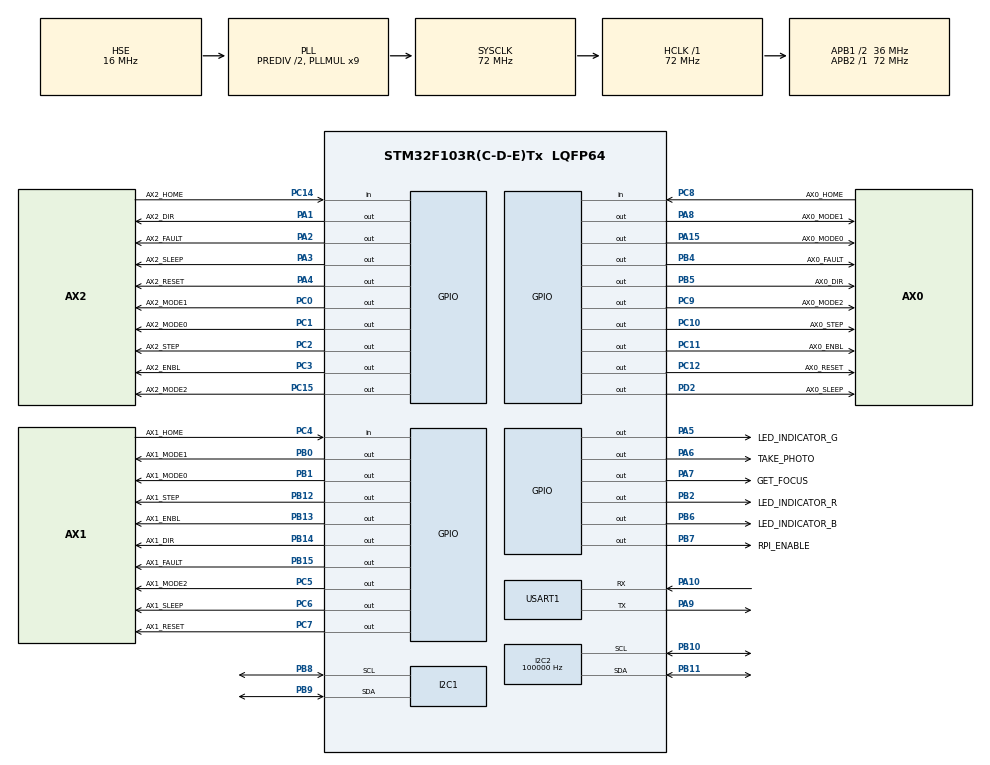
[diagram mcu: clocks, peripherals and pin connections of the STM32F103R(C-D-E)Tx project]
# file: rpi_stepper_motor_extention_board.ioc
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Dma.Request0=USART1_TX
Dma.Request1=USART1_RX
Dma.USART1_RX.1.Direction=DMA_PERIPH_TO_MEMORY
Dma.USART1_RX.1.Instance=DMA1_Channel5
Dma.USART1_RX.1.MemDataAlignment=DMA_MDATAALIGN_BYTE
Dma.USART1_RX.1.MemInc=DMA_MINC_ENABLE
Dma.USART1_RX.1.Mode=DMA_NORMAL
Dma.USART1_RX.1.PeriphDataAlignment=DMA_PDATAALIGN_BYTE
Dma.USART1_RX.1.PeriphInc=DMA_PINC_DISABLE
Dma.USART1_RX.1.Priority=DMA_PRIORITY_LOW
Dma.USART1_TX.0.Direction=DMA_MEMORY_TO_PERIPH
Dma.USART1_TX.0.Instance=DMA1_Channel4
Dma.USART1_TX.0.MemDataAlignment=DMA_MDATAALIGN_BYTE
Dma.USART1_TX.0.MemInc=DMA_MINC_ENABLE
Dma.USART1_TX.0.Mode=DMA_NORMAL
Dma.USART1_TX.0.PeriphDataAlignment=DMA_PDATAALIGN_BYTE
Dma.USART1_TX.0.PeriphInc=DMA_PINC_DISABLE
Dma.USART1_TX.0.Priority=DMA_PRIORITY_LOW
I2C2.ClockSpeed=100000
I2C2.GeneralCallMode=I2C_GENERALCALL_DISABLE
I2C2.I2C_Mode=I2C_Standard
I2C2.NoStretchMode=I2C_NOSTRETCH_DISABLE
I2C2.OwnAddress=0
Mcu.Family=STM32F1
Mcu.Name=STM32F103R(C-D-E)Tx
Mcu.Package=LQFP64
NVIC.DMA1_Channel4_IRQn=true\:0\:0\:false\:false\:true\:false\:true
NVIC.DMA1_Channel5_IRQn=true\:0\:0\:false\:false\:true\:false\:true
NVIC.I2C1_ER_IRQn=true\:0\:0\:false\:false\:true\:true\:true
NVIC.I2C1_EV_IRQn=true\:0\:0\:false\:false\:true\:true\:true
NVIC.I2C2_ER_IRQn=true\:1\:0\:true\:false\:true\:true\:true
NVIC.I2C2_EV_IRQn=true\:1\:0\:true\:false\:true\:true\:true
NVIC.PriorityGroup=NVIC_PRIORITYGROUP_4
NVIC.TIM4_IRQn=true\:0\:0\:false\:false\:true\:true\:true
NVIC.TIM5_IRQn=true\:0\:0\:false\:false\:true\:true\:true
NVIC.TIM6_IRQn=true\:0\:0\:false\:false\:true\:true\:true
NVIC.USART1_IRQn=true\:0\:0\:false\:false\:true\:true\:true
PA1.GPIO_Label=AX2_DIR
PA1.Signal=GPIO_Output
PA10.Mode=Asynchronous
PA10.Signal=USART1_RX
PA13.Mode=Trace_Asynchronous_SW
PA13.Signal=SYS_JTMS-SWDIO
PA14.Mode=Trace_Asynchronous_SW
PA14.Signal=SYS_JTCK-SWCLK
PA15.GPIO_Label=AX0_MODE0
PA15.Signal=GPIO_Output
PA2.GPIO_Label=AX2_FAULT
PA2.PinState=GPIO_PIN_SET
PA2.Signal=GPIO_Output
PA3.GPIO_Label=AX2_SLEEP
PA3.PinState=GPIO_PIN_SET
PA3.Signal=GPIO_Output
PA4.GPIO_Label=AX2_RESET
PA4.PinState=GPIO_PIN_SET
PA4.Signal=GPIO_Output
PA5.GPIO_Label=LED_INDICATOR_G
PA5.GPIO_PuPd=GPIO_PULLDOWN
PA5.Signal=GPIO_Output
PA6.GPIO_Label=TAKE_PHOTO
PA6.Signal=GPIO_Output
PA7.GPIO_Label=GET_FOCUS
PA7.Signal=GPIO_Output
PA8.GPIO_Label=AX0_MODE1
PA8.Signal=GPIO_Output
PA9.Mode=Asynchronous
PA9.Signal=USART1_TX
PB0.GPIO_Label=AX1_MODE1
PB0.Signal=GPIO_Output
PB1.GPIO_Label=AX1_MODE0
PB1.Signal=GPIO_Output
PB10.GPIO_Speed=GPIO_SPEED_FREQ_LOW
PB10.Mode=I2C
PB10.Signal=I2C2_SCL
PB11.GPIO_Speed=GPIO_SPEED_FREQ_LOW
PB11.Mode=I2C
PB11.Signal=I2C2_SDA
PB12.GPIO_Label=AX1_STEP
PB12.Signal=GPIO_Output
PB13.GPIO_Label=AX1_ENBL
PB13.PinState=GPIO_PIN_SET
PB13.Signal=GPIO_Output
PB14.GPIO_Label=AX1_DIR
PB14.Signal=GPIO_Output
PB15.GPIO_Label=AX1_FAULT
PB15.PinState=GPIO_PIN_SET
PB15.Signal=GPIO_Output
PB2.GPIO_Label=LED_INDICATOR_R
PB2.GPIO_PuPd=GPIO_PULLDOWN
PB2.Signal=GPIO_Output
PB3.Mode=Trace_Asynchronous_SW
PB3.Signal=SYS_JTDO-TRACESWO
PB4.GPIO_Label=AX0_FAULT
PB4.PinState=GPIO_PIN_SET
PB4.Signal=GPIO_Output
PB5.GPIO_Label=AX0_DIR
PB5.Signal=GPIO_Output
PB6.GPIO_Label=LED_INDICATOR_B
PB6.GPIO_PuPd=GPIO_PULLDOWN
PB6.Signal=GPIO_Output
PB7.GPIO_Label=RPI_ENABLE
PB7.Signal=GPIO_Output
PB8.Mode=I2C
PB8.Signal=I2C1_SCL
PB9.Mode=I2C
PB9.Signal=I2C1_SDA
PC0.GPIO_Label=AX2_MODE1
PC0.Signal=GPIO_Output
PC1.GPIO_Label=AX2_MODE0
PC1.Signal=GPIO_Output
PC10.GPIO_Label=AX0_STEP
PC10.Signal=GPIO_Output
PC11.GPIO_Label=AX0_ENBL
PC11.PinState=GPIO_PIN_SET
PC11.Signal=GPIO_Output
PC12.GPIO_Label=AX0_RESET
PC12.PinState=GPIO_PIN_SET
PC12.Signal=GPIO_Output
PC14-OSC32_IN.GPIO_Label=AX2_HOME
PC14-OSC32_IN.Signal=GPIO_Input
PC15-OSC32_OUT.GPIO_Label=AX2_MODE2
PC15-OSC32_OUT.Signal=GPIO_Output
PC2.GPIO_Label=AX2_STEP
PC2.Signal=GPIO_Output
PC3.GPIO_Label=AX2_ENBL
PC3.PinState=GPIO_PIN_SET
PC3.Signal=GPIO_Output
PC4.GPIO_Label=AX1_HOME
PC4.Signal=GPIO_Input
PC5.GPIO_Label=AX1_MODE2
PC5.Signal=GPIO_Output
PC6.GPIO_Label=AX1_SLEEP
PC6.PinState=GPIO_PIN_SET
PC6.Signal=GPIO_Output
PC7.GPIO_Label=AX1_RESET
PC7.PinState=GPIO_PIN_SET
PC7.Signal=GPIO_Output
PC8.GPIO_Label=AX0_HOME
PC8.Signal=GPIO_Input
PC9.GPIO_Label=AX0_MODE2
PC9.Signal=GPIO_Output
PD0-OSC_IN.Mode=HSE-External-Clock-Source
PD0-OSC_IN.Signal=RCC_OSC_IN
PD1-OSC_OUT.Mode=HSE-External-Clock-Source
PD1-OSC_OUT.Signal=RCC_OSC_OUT
PD2.GPIO_Label=AX0_SLEEP
PD2.PinState=GPIO_PIN_SET
PD2.Signal=GPIO_Output
ProjectManager.HeapSize=0x200
ProjectManager.StackSize=0x400
ProjectManager.TargetToolchain=STM32CubeIDE
RCC.AHBFreq_Value=72000000
RCC.APB1CLKDivider=RCC_HCLK_DIV2
RCC.APB1Freq_Value=36000000
RCC.APB1TimFreq_Value=72000000
RCC.APB2Freq_Value=72000000
RCC.APB2TimFreq_Value=72000000
RCC.HCLKFreq_Value=72000000
RCC.HSEDivPLL=RCC_HSE_PREDIV_DIV2
RCC.HSE_VALUE=16000000
RCC.PLLMUL=RCC_PLL_MUL9
RCC.PLLSourceVirtual=RCC_PLLSOURCE_HSE
RCC.SYSCLKFreq_VALUE=72000000
RCC.SYSCLKSource=RCC_SYSCLKSOURCE_PLLCLK
RCC.USBFreq_Value=72000000
TIM4.Period=99
TIM4.Prescaler=7199
TIM5.Period=9
TIM5.Prescaler=7199
TIM6.Period=9
TIM6.Prescaler=7199
USART1.VirtualMode=VM_ASYNC
VP_TIM4_VS_ClockSourceINT.Mode=Internal
VP_TIM5_VS_ClockSourceINT.Mode=Internal
VP_TIM6_VS_ClockSourceINT.Mode=Enable_Timer
board=custom

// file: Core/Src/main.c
/* USER CODE BEGIN Header */
/**
  ******************************************************************************
  * @file           : main.c
  * @brief          : Main program body
  ******************************************************************************
  * @attention
  *
  * <h2><center>&copy; Copyright (c) 2020 STMicroelectronics.
  * All rights reserved.</center></h2>
  *
  * This software component is licensed by ST under BSD 3-Clause license,
  * the "License"; You may not use this file except in compliance with the
  * License. You may obtain a copy of the License at:
  *                        opensource.org/licenses/BSD-3-Clause
  *
  ******************************************************************************
  */
/* USER CODE END Header */

#include "main.h"
#include "dma.h"
#include "i2c.h"
#include "tim.h"
#include "usart.h"
#include "gpio.h"

/* USER CODE BEGIN Includes */
#include "parser.h"
#include "parser_functions.h"
/* USER CODE END Includes */

void SystemClock_Config(void);

int main(void)
{

  /* MCU Configuration--------------------------------------------------------*/

  /* Reset of all peripherals, Initializes the Flash interface and the Systick. */
  HAL_Init();

  /* Configure the system clock */
  SystemClock_Config();

  /* Initialize all configured peripherals */
  MX_GPIO_Init();
  MX_DMA_Init();
  MX_I2C1_Init();
  MX_I2C2_Init();
  MX_TIM5_Init();
  MX_TIM4_Init();
  MX_USART1_UART_Init();
  MX_TIM6_Init();
  /* USER CODE BEGIN 2 */
  HAL_I2C_Init(&hi2c2);
  HAL_TIM_Base_Start_IT(&htim4);
  HAL_TIM_Base_Start_IT(&htim5);
  HAL_TIM_Base_Start_IT(&htim6);
  HAL_UART_Receive_DMA(&huart1, received, 1);
  register_uart_rx_event_callback(m_parser);

  HAL_GPIO_WritePin(RPI_ENABLE_GPIO_Port, RPI_ENABLE_Pin, GPIO_PIN_RESET);	/* Turn on RPi */
  init_masks();
  /* USER CODE END 2 */

  /* Infinite loop */
  while (1)
  {
	  UART_RX_EVENT(rx_buffer);
  }
}

void SystemClock_Config(void)
{
  RCC_OscInitTypeDef RCC_OscInitStruct = {0};
  RCC_ClkInitTypeDef RCC_ClkInitStruct = {0};

  /** Initializes the CPU, AHB and APB busses clocks
  */
  RCC_OscInitStruct.OscillatorType = RCC_OSCILLATORTYPE_HSE;
  RCC_OscInitStruct.HSEState = RCC_HSE_BYPASS;
  RCC_OscInitStruct.HSEPredivValue = RCC_HSE_PREDIV_DIV2;
  RCC_OscInitStruct.HSIState = RCC_HSI_ON;
  RCC_OscInitStruct.PLL.PLLState = RCC_PLL_ON;
  RCC_OscInitStruct.PLL.PLLSource = RCC_PLLSOURCE_HSE;
  RCC_OscInitStruct.PLL.PLLMUL = RCC_PLL_MUL9;
  if (HAL_RCC_OscConfig(&RCC_OscInitStruct) != HAL_OK)
  {
    Error_Handler();
  }
  /** Initializes the CPU, AHB and APB busses clocks
  */
  RCC_ClkInitStruct.ClockType = RCC_CLOCKTYPE_HCLK|RCC_CLOCKTYPE_SYSCLK
                              |RCC_CLOCKTYPE_PCLK1|RCC_CLOCKTYPE_PCLK2;
  RCC_ClkInitStruct.SYSCLKSource = RCC_SYSCLKSOURCE_PLLCLK;
  RCC_ClkInitStruct.AHBCLKDivider = RCC_SYSCLK_DIV1;
  RCC_ClkInitStruct.APB1CLKDivider = RCC_HCLK_DIV2;
  RCC_ClkInitStruct.APB2CLKDivider = RCC_HCLK_DIV1;

  if (HAL_RCC_ClockConfig(&RCC_ClkInitStruct, FLASH_LATENCY_2) != HAL_OK)
  {
    Error_Handler();
  }
}

void Error_Handler(void)
{
}

/************************ (C) COPYRIGHT STMicroelectronics *****END OF FILE****/
